# host_mcu_secure register map
Vendor: Texas Instruments
Peripheral module from a debugger description file (folder CC35X1).
Registers are 32-bit, access per field, reset values left out (the file's numbers can be read two ways) unless marked. A register's access mark holds for its fields unless they carry their own. Offsets are as the file gives them; lines under a group give offsets from that group; [hi:lo] are bit positions; {n}, {i} and the like mark numbered series; 'fields as' and 'values as' point back to an identical list; <NAME> marks a mode.

## host_mcu_secure
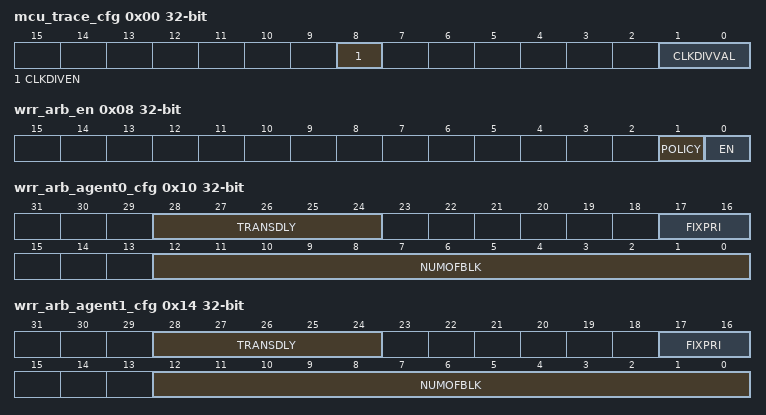
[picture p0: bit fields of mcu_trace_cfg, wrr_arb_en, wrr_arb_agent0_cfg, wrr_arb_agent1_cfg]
0x00 mcu_trace_cfg — Trace Configuration. Configuration register for CortexM3-TPIU (TRACE ports i/o unit)
  [8] CLKDIVEN wo — Set this register to load [CLKDIVVAL]
    0=DIS; 1=EN (Disable)
  [1:0] CLKDIVVAL rw — Configure TRACE-CLOCK divider value, for (TPIU - input clock) [1] - Divide by 2 - 'tpiu_trace_clk_in' = 40MHz [2] - Divide by 4 - 'tpiu_trace_clk_in' = 20MHz (Default) [0,3] - are not supported (do not use) AFTER setting this value - set [CLKDIVEN] to active this value
    0=DIV_2 (Divide by 2); 1=DIV_4 (Divide by 4)
0x04 mcu_spare rw — Spare
  [31:0] SBITS
0x08 wrr_arb_en — WRR Arbiter Enable Register
  [1] POLICY rw — Field to configure the priority policy 0 - Fixed Priority 1 - Round Robin (Default)
    0=FIXED (Fixed priority); 1=ROUNDROBIN (Round Robin (Default))
  [0] EN rw — Field to enable/select the arbitration logic 0 - Disabled, use SIE-200 arbitration logic. 1 - Enable, use wrapper arbitration logic.
    0=DIS (Use SIE-200 arbitration logic); 1=EN (Use wrapper arbitration logic)
0x10 wrr_arb_agent0_cfg — WRR Arbiter - Agent 0 Configuration
  [28:24] TRANSDLY rw — Number of cycle before starting to serve next agent in line. Up to 32 cycles.
  [17:16] FIXPRI rw — Field to select the fixed priority level 0 - Highest 1 - Medium 2 - Lowest (default) 3 - Not in Use
    0=SEL_0 (Highest Priority); 2=SEL_2 (Lowest priority (default)); 1=SEL_1 (Medium Priority)
  [12:0] NUMOFBLK rw — Number of words to be served in each arbitration grant. Up to 8,192 words (32KB). Value must be greater then 0.
0x14 wrr_arb_agent1_cfg — WRR Arbiter - Agent 1 Configuration
  [28:24] TRANSDLY rw — Number of cycle before starting to serve next agent in line. Up to 32 cycles.
  [17:16] FIXPRI rw — Field to select the fixed priority level 0 - Highest 1 - Medium 2 - Lowest (default) 3 - Not in Use
    0=SEL_0 (Highest priority); 1=SEL_1 (Medium priority); 2=SEL_2 (Lowest priority (default))
  [12:0] NUMOFBLK rw — Number of words to be served in each arbitration grant. Up to 8,192 words (32KB). Value must be greater then 0.
0x18 sw_timestamp — Software Timestamp Interrupt Register
  [15:0] TIMESTAMP rw — Field to write timestamp for ET bus.
0x1C ns_sw_interrupt_to_s — Non Secure Software Interrupt
  [3:0] EN rw — Non Secure context of CM33 can use this register to interrupt secure context of CM33.
0x20 sw_interrupt_to_cm3 — Software Interrupt to CM3
  [0] EN rw — Non Secure context of CM33 can use this register to interrupt CM3.
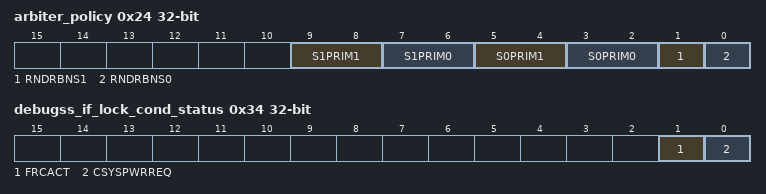
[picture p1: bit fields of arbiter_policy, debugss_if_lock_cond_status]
0x24 arbiter_policy — Arbiter Policy. Arbiter Policy for the arbiters(x2) located just before MEMSS Portion A and Portion B
  [9:8] S1PRIM1 rw — This bit field takes affect when Fixed Priority is selected for the arbiter before MEMSS Portion B. This field is used to configure the priority of ocp.
  [7:6] S1PRIM0 rw — This bit field takes affect when Fixed Priority is selected for the arbiter before MEMSS Portion B. This field is used to configure the priority of udma/sahb.
  [5:4] S0PRIM1 rw — This bit field takes affect when Fixed Priority is selected for the arbiter before MEMSS Portion A. This field is used to configure the priority of ocp.
  [3:2] S0PRIM0 rw — This bit field takes affect when Fixed Priority is selected for the arbiter before MEMSS Portion A. This field is used to configure the priority of udma/sahb.
  [1] RNDRBNS1 rw — Field to select the arbitration policy of second arbiter (MEMSS Portion ) 1 -> Round Robin is enabled 0 -> Fixed priority is enabled
    0=FIXED (Fixed priority); 1=ROUNDROBIN (Round Robin priority)
  [0] RNDRBNS0 rw — Field to select the arbitration policy of second arbiter (MEMSS Portion A) 1 -> Round Robin is enabled 0 -> Fixed priority is enabled
    values as RNDRBNS1
0x28 debugss — DEBUGSS Control Register.
  fields as sw_interrupt_to_cm3
0x2C debugss_if_lock — DEBUGSS Interface Lock.
  [0] LOCK rw — The method: Obtain lock by Read. Following are all s/w operation possibilities: When reading '1' - lock is obtained. (i.e. no debugss request was active during the rd transaction). When reading '0' - lock is not obtained. Try to read again. (i.e. at least debugss request event was active during the rd transaction). when writing '1' - lock will be obtained regardless to debugss request status when writing '0' - lock will be released. Type: Write/Read-Clear
0x30 debugss_if_lock_cond_mask — DEBUGSS Interface Lock Condition Mask
  [1] MASK rw — Masks Debugss Force-active Set 1 - Mask request during lock check. Set 0 - O.W.
    0=SET_0 (O.W); 1=SET_1 (Mask request during lock check)
0x34 debugss_if_lock_cond_status ro — DEBUGSS Interface Lock Condition Status
  [1] FRCACT — DEBUGSS HOST Force Active
    0=CLR (Not in use); 1=SET (Debugss host force active is set)
  [0] CSYSPWRREQ — DEBUGSS HOST C SYS Power Request
    0=CLR (Not in use); 1=SET (Debugss host c sys power requested)
